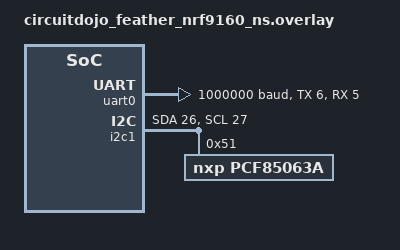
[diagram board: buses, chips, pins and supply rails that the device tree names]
/ {
	aliases {
		bootloader-led0 = &blue_led;
    };
};

// Full speed ahead
&uart0 {
	status = "okay";
	current-speed = <1000000>;
	tx-pin = <6>;
	rx-pin = <5>;
};

// Enable External RTC
&i2c1 {
	compatible = "nordic,nrf-twim";
	status = "okay";
	sda-pin = <26>;
	scl-pin = <27>;

	pcf85063a@51 {
		compatible = "nxp,pcf85063a";
		label = "PCF85063A";
		reg = <0x51>;
	};
};
